# STM32GBK1CBT6 register map
File version: 2.1
CPU: CM4 r0p1, little endian, MPU, FPU, 4 interrupt priority bits
Registers are 32-bit, read-write, reset 0x0 unless marked. A register's access mark holds for its fields unless they carry their own. Offsets are from the block's base; [hi:lo] are bit positions; {n}, {i} and the like mark numbered series.

## GPIOA — General-purpose I/Os
Base 0x48000000
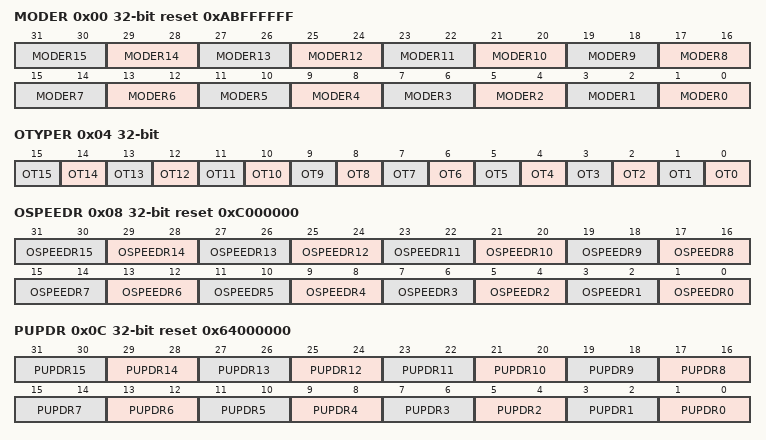
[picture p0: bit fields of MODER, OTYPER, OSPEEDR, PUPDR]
0x00 MODER reset 0xABFFFFFF — GPIO port mode register
  [2n+1:2n] MODER{n} (n=0..15) — Port x configuration bits (y = 0..15)
0x04 OTYPER — GPIO port output type register
  [n] OT{n} (n=0..15) — Port x configuration bits (y = 0..15)
0x08 OSPEEDR reset 0xC000000 — GPIO port output speed register
  [2n+1:2n] OSPEEDR{n} (n=0..15) — Port x configuration bits (y = 0..15)
0x0C PUPDR reset 0x64000000 — GPIO port pull-up/pull-down register
  [2n+1:2n] PUPDR{n} (n=0..15) — Port x configuration bits (y = 0..15)
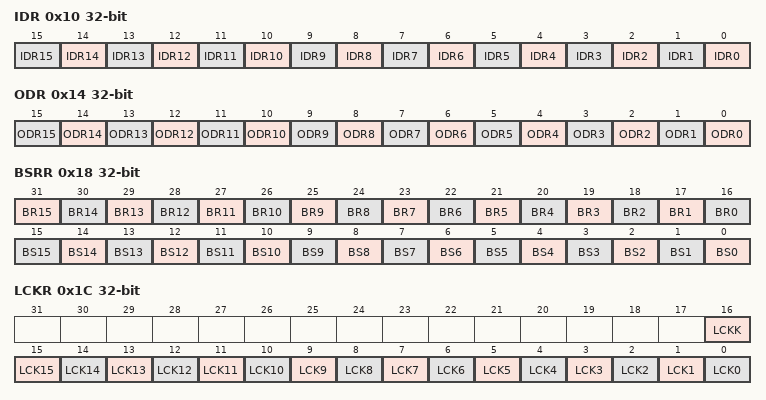
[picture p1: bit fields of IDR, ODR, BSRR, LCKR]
0x10 IDR ro — GPIO port input data register
  [n] IDR{n} (n=0..15) — Port input data (y = 0..15)
0x14 ODR — GPIO port output data register
  [n] ODR{n} (n=0..15) — Port output data (y = 0..15)
0x18 BSRR wo — GPIO port bit set/reset register
  [n+16] BR{n} (n=1..15) — Port x reset bit y (y = 0..15)
  [16] BR0 — Port x set bit y (y= 0..15)
  [n] BS{n} (n=0..15) — Port x set bit y (y= 0..15)
0x1C LCKR — GPIO port configuration lock register
  [16] LCKK — Port x lock bit y (y= 0..15)
  [n] LCK{n} (n=0..15) — Port x lock bit y (y= 0..15)
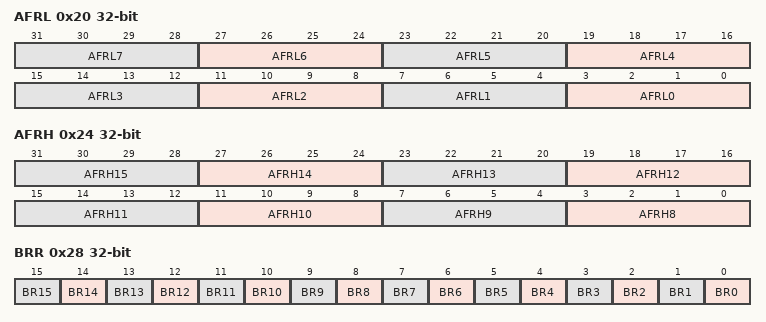
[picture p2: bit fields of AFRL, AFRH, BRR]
0x20 AFRL — GPIO alternate function low register
  [4n+3:4n] AFRL{n} (n=0..7) — Alternate function selection for port x bit y (y = 0..7)
0x24 AFRH — GPIO alternate function high register
  [4n-29:4n-32] AFRH{n} (n=8..15) — Alternate function selection for port x bit y (y = 8..15)
0x28 BRR wo — GPIO port bit reset register
  [n] BR{n} (n=0..15) — Port Reset bit

## GPIOB — General-purpose I/Os
Base 0x48000400
Registers as GPIOA; these are added or differ:
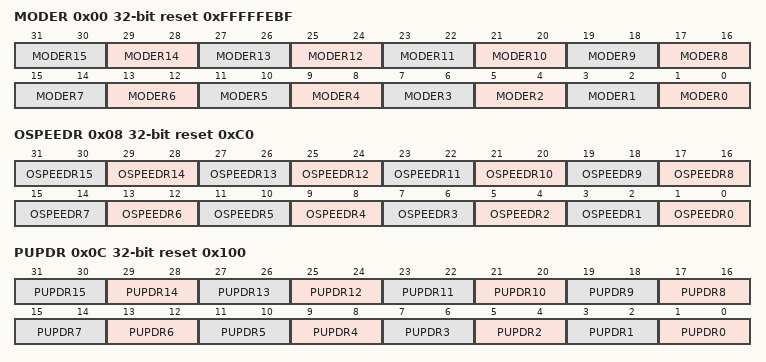
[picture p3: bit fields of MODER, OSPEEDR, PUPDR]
0x00 MODER reset 0xFFFFFEBF — GPIO port mode register
  [2n+1:2n] MODER{n} (n=0..15) — Port x configuration bits (y = 0..15)
0x08 OSPEEDR reset 0xC0 — GPIO port output speed register
  [2n+1:2n] OSPEEDR{n} (n=0..15) — Port x configuration bits (y = 0..15)
0x0C PUPDR reset 0x100 — GPIO port pull-up/pull-down register
  [2n+1:2n] PUPDR{n} (n=0..15) — Port x configuration bits (y = 0..15)

## GPIOC — General-purpose I/Os
Base 0x48000800
Same registers: GPIOD 0x48000C00, GPIOE 0x48001000, GPIOF 0x48001400, GPIOG 0x48001800
Registers as GPIOA; these are added or differ:
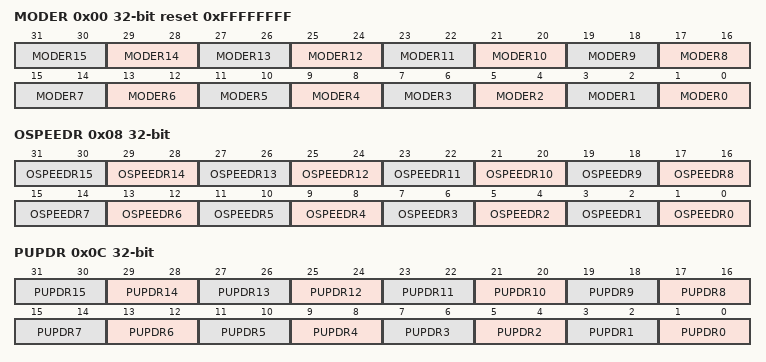
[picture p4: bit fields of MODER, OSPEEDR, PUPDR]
0x00 MODER reset 0xFFFFFFFF — GPIO port mode register
  [2n+1:2n] MODER{n} (n=0..15) — Port x configuration bits (y = 0..15)
0x08 OSPEEDR — GPIO port output speed register
  [2n+1:2n] OSPEEDR{n} (n=0..15) — Port x configuration bits (y = 0..15)
0x0C PUPDR — GPIO port pull-up/pull-down register
  [2n+1:2n] PUPDR{n} (n=0..15) — Port x configuration bits (y = 0..15)

## TIM6 — Basic-timers
Base 0x40001000
Same registers: TIM7 0x40001400
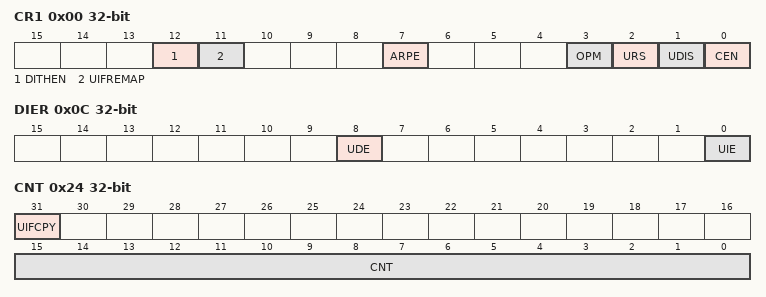
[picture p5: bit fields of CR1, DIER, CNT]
0x00 CR1 — control register 1
  [12] DITHEN — Dithering Enable
  [11] UIFREMAP — UIF status bit remapping
  [7] ARPE — Auto-reload preload enable
  [3] OPM — One-pulse mode
  [2] URS — Update request source
  [1] UDIS — Update disable
  [0] CEN — Counter enable
0x04 CR2 — control register 2
  [6:4] MMS — Master mode selection
0x0C DIER — DMA/Interrupt enable register
  [8] UDE — Update DMA request enable
  [0] UIE — Update interrupt enable
0x10 SR — status register
  [0] UIF — Update interrupt flag
0x14 EGR wo — event generation register
  [0] UG — Update generation
0x24 CNT access per field — counter
  [31] UIFCPY ro — UIF Copy
  [15:0] CNT rw — Low counter value
0x28 PSC — prescaler
  [15:0] PSC — Prescaler value
0x2C ARR reset 0xFFFF — auto-reload register
  [15:0] ARR — Low Auto-reload value

## LPTIMER1 — Low power timer
Base 0x40007C00
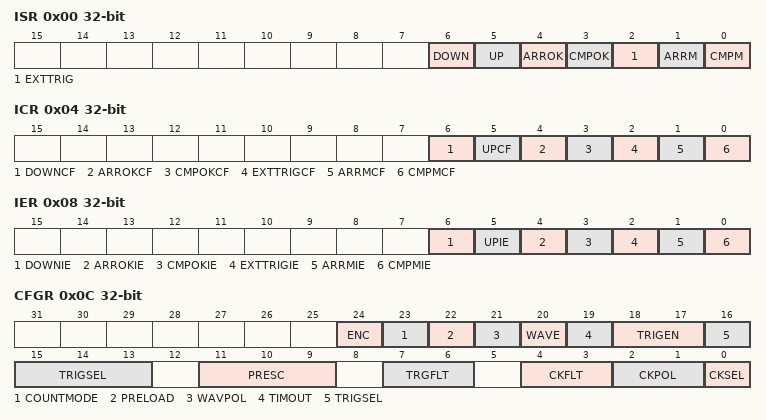
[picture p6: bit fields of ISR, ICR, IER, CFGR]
0x00 ISR ro — Interrupt and Status Register
  [6] DOWN — Counter direction change up to down
  [5] UP — Counter direction change down to up
  [4] ARROK — Autoreload register update OK
  [3] CMPOK — Compare register update OK
  [2] EXTTRIG — External trigger edge event
  [1] ARRM — Autoreload match
  [0] CMPM — Compare match
0x04 ICR wo — Interrupt Clear Register
  [6] DOWNCF — Direction change to down Clear Flag
  [5] UPCF — Direction change to UP Clear Flag
  [4] ARROKCF — Autoreload register update OK Clear Flag
  [3] CMPOKCF — Compare register update OK Clear Flag
  [2] EXTTRIGCF — External trigger valid edge Clear Flag
  [1] ARRMCF — Autoreload match Clear Flag
  [0] CMPMCF — compare match Clear Flag
0x08 IER — Interrupt Enable Register
  [6] DOWNIE — Direction change to down Interrupt Enable
  [5] UPIE — Direction change to UP Interrupt Enable
  [4] ARROKIE — Autoreload register update OK Interrupt Enable
  [3] CMPOKIE — Compare register update OK Interrupt Enable
  [2] EXTTRIGIE — External trigger valid edge Interrupt Enable
  [1] ARRMIE — Autoreload match Interrupt Enable
  [0] CMPMIE — Compare match Interrupt Enable
0x0C CFGR — Configuration Register
  [24] ENC — Encoder mode enable
  [23] COUNTMODE — counter mode enabled
  [22] PRELOAD — Registers update mode
  [21] WAVPOL — Waveform shape polarity
  [20] WAVE — Waveform shape
  [19] TIMOUT — Timeout enable
  [18:17] TRIGEN — Trigger enable and polarity
  [16:13] TRIGSEL — Trigger selector
  [11:9] PRESC — Clock prescaler
  [7:6] TRGFLT — Configurable digital filter for trigger
  [4:3] CKFLT — Configurable digital filter for external clock
  [2:1] CKPOL — Clock Polarity
  [0] CKSEL — Clock selector
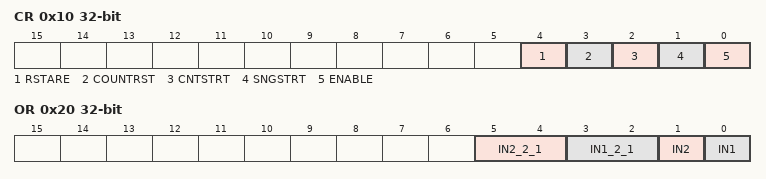
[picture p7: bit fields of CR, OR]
0x10 CR — Control Register
  [4] RSTARE
  [3] COUNTRST
  [2] CNTSTRT — Timer start in continuous mode
  [1] SNGSTRT — LPTIM start in single mode
  [0] ENABLE — LPTIM Enable
0x14 CMP — Compare Register
  [15:0] CMP — Compare value
0x18 ARR reset 0x1 — Autoreload Register
  [15:0] ARR — Auto reload value
0x1C CNT ro — Counter Register
  [15:0] CNT — Counter value
0x20 OR — option register
  [5:4] IN2_2_1, [3:2] IN1_2_1, [1] IN2, [0] IN1

## Notices in the file
Copyright (c) 2023 STMicroelectronics.
SPDX-License-Identifier: Apache-2.0
Licensed under the Apache License, Version 2.0 (the "License");
you may not use this file except in compliance with the License.
You may obtain a copy of the License at
http://www.apache.org/licenses/LICENSE-2.0
Unless required by applicable law or agreed to in writing, software
distributed under the License is distributed on an "AS IS" BASIS,
WITHOUT WARRANTIES OR CONDITIONS OF ANY KIND, either express or implied.
See the License for the specific language governing permissions and
limitations under the License.
